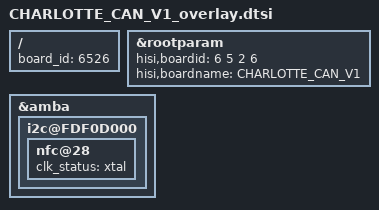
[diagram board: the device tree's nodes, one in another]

/**
 * Copyright (C) 2014 Hisilicon Ltd.
 *
 *  This program is free software; you can redistribute it and/or modify
 *  it under the terms of the GNU General Public License version 2 as
 *  publishhed by the Free Software Foundation.
 */

/include/ "CHARLOTTE_LX9_V3_overlay.dtsi"

/ {
        board_id = <6526>;
};

&rootparam {
    hisi,boardid = <6 5 2 6>;
    hisi,boardname = "CHARLOTTE_CAN_V1";
};


&amba {
    i2c@FDF0D000 {
        nfc@28 {
            clk_status ="xtal";
        };
    };
};
